# STM32L452xx register map
File version: 1.0
Registers are 32-bit, access not given, reset 0x0 unless marked. A register's access mark holds for its fields unless they carry their own. Offsets are from the block's base; [hi:lo] are bit positions; {n}, {i} and the like mark numbered series.

## DMA1_CSELR
Base 0x400200A8
Same registers: DMA2_CSELR 0x400204A8
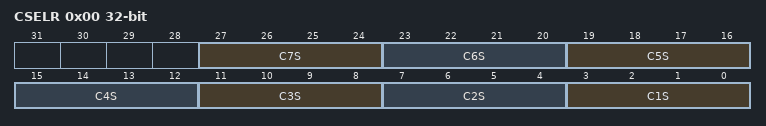
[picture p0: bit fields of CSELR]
0x00 CSELR
  [4n-1:4n-4] C{n}S (n=1..7)

## FLASH
Base 0x40022000
0x00 ACR
  [31] LOCK, [31] ECCD, [31] PCROP_RDP, [30] OPTLOCK, [30] ECCC, [27] OBL_LAUNCH, [27] nBOOT0, [26] RDERRIE, [26] nSWBOOT0, [25] ERRIE, [25] SRAM2_RST, [24] EOPIE, [24] ECCIE, [24] SRAM2_PE, [23] nBOOT1, [20] SYSF_ECC, [19] WWDG_SW, [18] FSTPG, [18] IWDG_STDBY, [17] PEMPTY, [17] OPTSTRT, [17] IWDG_STOP, [16] BSY, [16] STRT, [16] IWDG_SW, [23:16] WRP1A_END, [23:16] WRP1B_END, [15] OPTVERR, [14] SLEEP_PD, [14] RDERR, [14] nRST_SHDW, [13] RUN_PD, [13] nRST_STDBY, [12] DCRST, [12] nRST_STOP, [11] ICRST, [10] DCEN, [9] ICEN, [9] FASTERR, [8] PRFTEN, [8] MISERR, [10:8] BOR_LEV, [7] PGSERR, [6] SIZERR, [5] PGAERR, [4] WRPERR, [3] PROGERR, [10:3] PNB, [2] MER1, [1] OPERR, [1] PER, [2:0] LATENCY, [0] EOP, [0] PG, [18:0] ADDR_ECC, [7:0] RDP, [15:0] PCROP1_STRT, [15:0] PCROP1_END, [7:0] WRP1A_STRT, [7:0] WRP1B_STRT
0x04 PDKEYR
0x08 KEYR
0x0C OPTKEYR
0x10 SR
0x14 CR
0x18 ECCR
0x20 OPTR
0x24 PCROP1SR
0x28 PCROP1ER
0x2C WRP1AR
0x30 WRP1BR

## CRC
Base 0x40023000
0x00 DR
  [7] REV_OUT, [6:5] REV_IN, [4:3] POLYSIZE, [31:0] DR, [7:0] IDR, [0] RESET, [31:0] INIT, [31:0] POL
0x04 IDR 8-bit
0x08 CR
0x10 INIT
0x14 POL

## TSC
Base 0x40024000
0x00 CR
  [31:28] CTPH, [27] G7_IO4, [27] G7_IO4, [27] G7_IO4, [27] G7_IO4, [26] G7_IO3, [26] G7_IO3, [26] G7_IO3, [26] G7_IO3, [25] G7_IO2, [25] G7_IO2, [25] G7_IO2, [25] G7_IO2, [27:24] CTPL, [24] G7_IO1, [24] G7_IO1, [24] G7_IO1, [24] G7_IO1, [23] G6_IO4, [23] G6_IO4, [23] G6_IO4, [23] G6_IO4, [22] G6_IO3, [22] G6_IO3, [22] G6_IO3, [22] G6_IO3, [n+15] G{n}S (n=1..7), [21] G6_IO2, [21] G6_IO2, [21] G6_IO2, [21] G6_IO2, [20] G6_IO1, [20] G6_IO1, [20] G6_IO1, [20] G6_IO1, [19] G5_IO4, [19] G5_IO4, [19] G5_IO4, [19] G5_IO4, [18] G5_IO3, [18] G5_IO3, [18] G5_IO3, [18] G5_IO3, [23:17] SSD, [17] G5_IO2, [17] G5_IO2, [17] G5_IO2, [17] G5_IO2, [16] SSE, [16] G5_IO1, [16] G5_IO1, [16] G5_IO1, [16] G5_IO1, [15] SSPSC, [15] G4_IO4, [15] G4_IO4, [15] G4_IO4, [15] G4_IO4, [14] G4_IO3, [14] G4_IO3, [14] G4_IO3, [14] G4_IO3, [13] G4_IO2, [13] G4_IO2, [13] G4_IO2, [13] G4_IO2, [14:12] PGPSC, [12] G4_IO1, [12] G4_IO1, [12] G4_IO1, [12] G4_IO1, [11] G3_IO4, [11] G3_IO4, [11] G3_IO4, [11] G3_IO4, [10] G3_IO3, [10] G3_IO3, [10] G3_IO3, [10] G3_IO3, [9] G3_IO2, [9] G3_IO2, [9] G3_IO2, [9] G3_IO2, [8] G3_IO1, [8] G3_IO1, [8] G3_IO1, [8] G3_IO1, [7] G2_IO4, [7] G2_IO4, [7] G2_IO4, [7] G2_IO4, [6] G2_IO3, [6] G2_IO3, [6] G2_IO3, [6] G2_IO3, [n-1] G{n}E (n=1..7), [7:5] MCV, [5] G2_IO2, [5] G2_IO2, [5] G2_IO2, [5] G2_IO2, [4] IODEF, [4] G2_IO1, [4] G2_IO1, [4] G2_IO1, [4] G2_IO1, [3] SYNCPOL, [3] G1_IO4, [3] G1_IO4, [3] G1_IO4, [3] G1_IO4, [2] AM, [2] G1_IO3, [2] G1_IO3, [2] G1_IO3, [2] G1_IO3, [1] START, [1] MCEIE, [1] MCEIC, [1] MCEF, [1] G1_IO2, [1] G1_IO2, [1] G1_IO2, [1] G1_IO2, [0] TSCE, [0] EOAIE, [0] EOAIC, [0] EOAF, [0] G1_IO1, [0] G1_IO1, [0] G1_IO1, [0] G1_IO1, [13:0] CNT, [13:0] CNT, [13:0] CNT, [13:0] CNT, [13:0] CNT, [13:0] CNT, [13:0] CNT
0x04 IER
0x08 ICR
0x0C ISR
0x10 IOHCR
0x18 IOASCR
0x20 IOSCR
0x28 IOCCR
0x30 IOGCSR
0x34 IOGXCR.0
0x38 IOGXCR.1
0x3C IOGXCR.2
0x40 IOGXCR.3
0x44 IOGXCR.4
0x48 IOGXCR.5
0x4C IOGXCR.6

## GPIOA
Base 0x48000000
Same registers: GPIOB 0x48000400, GPIOC 0x48000800, GPIOD 0x48000C00, GPIOE 0x48001000, GPIOH 0x48001C00
0x00 MODER
  [31] BR15, [2n+1:2n] MODE{n} (n=0..15), [2n+1:2n] OSPEED{n} (n=0..15), [2n+1:2n] PUPD{n} (n=0..15), [30] BR14, [29] BR13, [28] BR12, [4n+3:4n] AFSEL{n} (n=0..7), [4n-29:4n-32] AFSEL{n} (n=8..15), [27] BR11, [26] BR10, [25] BR9, [24] BR8, [23] BR7, [22] BR6, [21] BR5, [20] BR4, [19] BR3, [18] BR2, [17] BR1, [16] BR0, [16] LCKK, [n] OT{n} (n=0..15), [n] ID{n} (n=0..15), [n] OD{n} (n=0..15), [n] BS{n} (n=0..15), [n] LCK{n} (n=0..15), [15] BR15, [14] BR14, [13] BR13, [12] BR12, [11] BR11, [10] BR10, [9] BR9, [8] BR8, [7] BR7, [6] BR6, [5] BR5, [4] BR4, [3] BR3, [2] BR2, [1] BR1, [0] BR0
0x04 OTYPER
0x08 OSPEEDR
0x0C PUPDR
0x10 IDR
0x14 ODR
0x18 BSRR
0x1C LCKR
0x20 AFR.0
0x24 AFR.1
0x28 BRR

## ADC1
Base 0x50040000
0x00 ISR
  [31] ADCAL, [31] JQDIS, [31] SMPPLUS, [31] OFFSET{n}_EN (n=1..4), [30] ADCALDIF, [29] DEEPPWD, [28] ADVREGEN, [3n+2:3n] SMP{n} (n=0..9), [30:26] AWD1CH, [6n+6:6n+2] JSQ{n} (n=1..4), [30:26] OFFSET{n}_CH (n=1..4), [25] JAUTO, [24] JAWD1EN, [3n-28:3n-30] SMP{n} (n=10..18), [6n+4:6n] SQ{n} (n=1..4), [6n-26:6n-30] SQ{n} (n=5..9), [6n-56:6n-60] SQ{n} (n=10..14), [24] VBATEN, [23] AWD1EN, [23] TSEN, [22] AWD1SGL, [22] VREFEN, [21] JQM, [20] JDISCEN, [21:18] PRESC, [19:17] DISCNUM, [16] DISCEN, [27:16] HT1, [23:16] HT2, [23:16] HT3, [22:16] CALFACT_D, [17:16] CKMODE, [14] AUTDLY, [13] CONT, [12] OVRMOD, [10] JQOVF, [10] JQOVFIE, [11:10] EXTEN, [10] ROVSM, [9] AWD3, [9] AWD3IE, [9] TROVS, [8] AWD2, [8] AWD2IE, [7] AWD1, [7] AWD1IE, [6] JEOS, [6] JEOSIE, [9:6] EXTSEL, [10:6] SQ16, [7:6] JEXTEN, [5] JEOC, [5] JEOCIE, [5] JADSTP, [5] ALIGN, [8:5] OVSS, [4] OVR, [4] OVRIE, [4] ADSTP, [3] EOS, [3] EOSIE, [3] JADSTART, [4:3] RES, [2] EOC, [2] EOCIE, [2] ADSTART, [2] DFSDMCFG, [4:2] OVSR, [5:2] JEXTSEL, [1] EOSMP, [1] EOSMPIE, [1] ADDIS, [1] DMACFG, [1] JOVSE, [0] ADRDY, [0] ADRDYIE, [0] ADEN, [0] DMAEN, [0] ROVSE, [11:0] LT1, [7:0] LT2, [7:0] LT3, [3:0] L, [4:0] SQ15, [15:0] RDATA, [1:0] JL, [11:0] OFFSET{n} (n=1..4), [15:0] JDATA, [15:0] JDATA, [15:0] JDATA, [15:0] JDATA, [18:0] AWD2CH, [18:0] AWD3CH, [18:0] DIFSEL, [6:0] CALFACT_S
0x04 IER
0x08 CR
0x0C CFGR
0x10 CFGR2
0x14 SMPR1
0x18 SMPR2
{0x1C+4i} TR{i} (i=1..3)
{0x2C+4i} SQR{i} (i=1..4)
0x40 DR
0x4C JSQR
{0x5C+4i} OFR{i} (i=1..4)
{0x7C+4i} JDR{i} (i=1..4)
0xA0 AWD2CR
0xA4 AWD3CR
0xB0 DIFSEL
0xB4 CALFACT
0x308 CCR

## RNG
Base 0x50060800
0x00 CR
  [6] SEIS, [5] CEIS, [3] IE, [2] RNGEN, [2] SECS, [1] CECS, [0] DRDY
0x04 SR
0x08 DR

## QUADSPI
Base 0xA0001000
0x00 CR
  [31] DDRM, [30] DHHC, [28] SIOO, [27:26] FMODE, [31:24] PRESCALER, [25:24] DMODE, [23] PMM, [22] APMS, [20] TOIE, [19] SMIE, [18] FTIE, [22:18] DCYC, [17] TCIE, [16] TEIE, [20:16] FSIZE, [17:16] ABSIZE, [15:14] ABMODE, [13:12] ADSIZE, [11:10] ADMODE, [11:8] FTHRES, [10:8] CSHT, [12:8] FLEVEL, [9:8] IMODE, [7] FSEL, [6] DFM, [5] BUSY, [4] SSHIFT, [4] TOF, [4] CTOF, [3] TCEN, [3] SMF, [3] CSMF, [2] DMAEN, [2] FTF, [1] ABORT, [1] TCF, [1] CTCF, [0] EN, [0] CKMODE, [0] TEF, [0] CTEF, [31:0] DL, [7:0] INSTRUCTION, [31:0] ADDRESS, [31:0] ALTERNATE, [31:0] DATA, [31:0] MASK, [31:0] MATCH, [15:0] INTERVAL, [15:0] TIMEOUT
0x04 DCR
0x08 SR
0x0C FCR
0x10 DLR
0x14 CCR
0x18 AR
0x1C ABR
0x20 DR
0x24 PSMKR
0x28 PSMAR
0x2C PIR
0x30 LPTR

## DBGMCU
Base 0xE0042000
0x00 IDCODE
  [31] DBG_LPTIM1_STOP, [25] DBG_CAN_STOP, [23] DBG_I2C3_STOP, [22] DBG_I2C2_STOP, [21] DBG_I2C1_STOP, [17] DBG_TIM16_STOP, [31:16] REV_ID, [16] DBG_TIM15_STOP, [12] DBG_IWDG_STOP, [11] DBG_WWDG_STOP, [11] DBG_TIM1_STOP, [10] DBG_RTC_STOP, [7:6] TRACE_MODE, [5] TRACE_IOEN, [5] DBG_LPTIM2_STOP, [4] DBG_TIM6_STOP, [2] DBG_STANDBY, [1] DBG_STOP, [1] DBG_TIM3_STOP, [1] DBG_I2C4_STOP, [11:0] DEV_ID, [0] DBG_SLEEP, [0] DBG_TIM2_STOP
0x04 CR
0x08 APB1FZR1
0x0C APB1FZR2
0x10 APB2FZ
